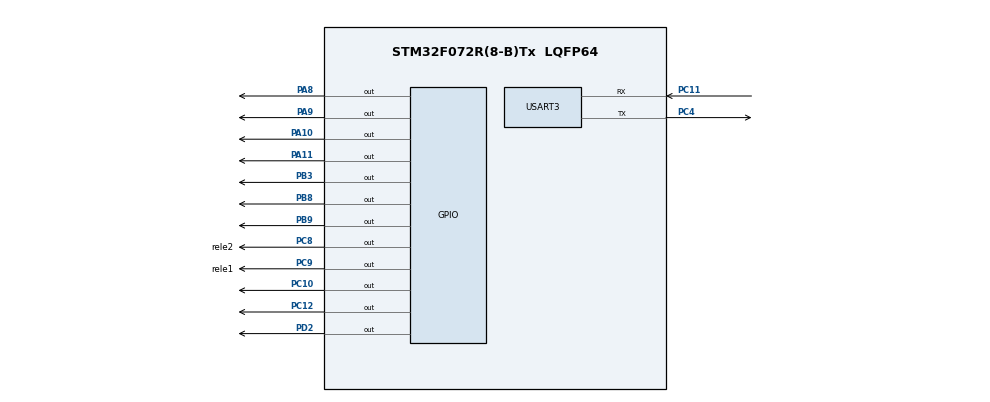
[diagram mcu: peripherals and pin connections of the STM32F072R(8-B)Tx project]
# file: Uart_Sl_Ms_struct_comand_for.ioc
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Mcu.Family=STM32F0
Mcu.Name=STM32F072R(8-B)Tx
Mcu.Package=LQFP64
NVIC.USART3_4_IRQn=true\:0\:0\:false\:false\:true\:true
PA10.Signal=GPIO_Output
PA11.Signal=GPIO_Output
PA8.Signal=GPIO_Output
PA9.Signal=GPIO_Output
PB3.Signal=GPIO_Output
PB8.GPIO_ModeDefaultOutputPP=GPIO_MODE_OUTPUT_PP
PB8.GPIO_PuPd=GPIO_PULLDOWN
PB8.PinState=GPIO_PIN_RESET
PB8.Signal=GPIO_Output
PB9.GPIO_PuPd=GPIO_PULLDOWN
PB9.PinState=GPIO_PIN_RESET
PB9.Signal=GPIO_Output
PC10.Signal=GPIO_Output
PC11.Mode=Asynchronous
PC11.Signal=USART3_RX
PC12.Signal=GPIO_Output
PC4.Mode=Asynchronous
PC4.Signal=USART3_TX
PC8.GPIO_Label=rele2
PC8.Signal=GPIO_Output
PC9.GPIO_Label=rele1
PC9.Signal=GPIO_Output
PD2.Signal=GPIO_Output
ProjectManager.HeapSize=0x200
ProjectManager.StackSize=0x400
ProjectManager.TargetToolchain=MDK-ARM V5
USART3.VirtualMode-Asynchronous=VM_ASYNC
USART3.WordLength=WORDLENGTH_8B
board=Uart_Sl_Ms_struct_comand_for

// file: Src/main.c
/**
  ******************************************************************************
  * @file           : main.c
  * @brief          : Main program body
  ******************************************************************************
  ** This notice applies to any and all portions of this file
  * that are not between comment pairs USER CODE BEGIN and
  * USER CODE END. Other portions of this file, whether
  * inserted by the user or by software development tools
  * are owned by their respective copyright owners.
  *
  * COPYRIGHT(c) 2018 STMicroelectronics
  *
  * Redistribution and use in source and binary forms, with or without modification,
  * are permitted provided that the following conditions are met:
  *   1. Redistributions of source code must retain the above copyright notice,
  *      this list of conditions and the following disclaimer.
  *   2. Redistributions in binary form must reproduce the above copyright notice,
  *      this list of conditions and the following disclaimer in the documentation
  *      and/or other materials provided with the distribution.
  *   3. Neither the name of STMicroelectronics nor the names of its contributors
  *      may be used to endorse or promote products derived from this software
  *      without specific prior written permission.
  *
  * THIS SOFTWARE IS PROVIDED BY THE COPYRIGHT HOLDERS AND CONTRIBUTORS "AS IS"
  * AND ANY EXPRESS OR IMPLIED WARRANTIES, INCLUDING, BUT NOT LIMITED TO, THE
  * IMPLIED WARRANTIES OF MERCHANTABILITY AND FITNESS FOR A PARTICULAR PURPOSE ARE
  * DISCLAIMED. IN NO EVENT SHALL THE COPYRIGHT HOLDER OR CONTRIBUTORS BE LIABLE
  * FOR ANY DIRECT, INDIRECT, INCIDENTAL, SPECIAL, EXEMPLARY, OR CONSEQUENTIAL
  * DAMAGES (INCLUDING, BUT NOT LIMITED TO, PROCUREMENT OF SUBSTITUTE GOODS OR
  * SERVICES; LOSS OF USE, DATA, OR PROFITS; OR BUSINESS INTERRUPTION) HOWEVER
  * CAUSED AND ON ANY THEORY OF LIABILITY, WHETHER IN CONTRACT, STRICT LIABILITY,
  * OR TORT (INCLUDING NEGLIGENCE OR OTHERWISE) ARISING IN ANY WAY OUT OF THE USE
  * OF THIS SOFTWARE, EVEN IF ADVISED OF THE POSSIBILITY OF SUCH DAMAGE.
  *
  ******************************************************************************
  */
#include "main.h"
#include "stm32f0xx_hal.h"

/* USER CODE BEGIN Includes */
     #define PROTOCOL_FAULT_TIMEOUT 			((uint8_t)0x01)
     #define PROTOCOL_FAULT_BADCRC 			((uint8_t)0x02)
     #define PROTOCOL_FAULT_UNKNOWNDATATYPE		((uint8_t)0x03)
     #define PROTOCOL_FAULT_UNKNOWNPAYLOAD		((uint8_t)0x04)
     #define PROTOCOL_FAULT_UNKNOWNLENGHT		((uint8_t)0x05)

/* USER CODE END Includes */

UART_HandleTypeDef huart3;

/* USER CODE BEGIN PV */
/* Private variables ---------------------------------------------------------*/
char Uart_texTX[]="Hi";
uint8_t Uart_texRX[8]	;
uint8_t uart_transmit[10];
uint8_t It =0;
uint8_t buff=0;

/* USER CODE END PV */
// typedef struct
// {	}Uart_Tx_OK_t ;

	/* Private function prototypes -----------------------------------------------*/
void SystemClock_Config(void);
static void MX_GPIO_Init(void);
static void MX_USART3_UART_Init(void);

/* USER CODE BEGIN PFP */
/* Private function prototypes -----------------------------------------------*/

/* USER CODE END PFP */

int main(void)
{
  /* USER CODE BEGIN 1 */
	for (uint8_t i =0; i<10;i++)
	{
		uart_transmit[i]=i;
	}

  /* USER CODE END 1 */

  /* MCU Configuration----------------------------------------------------------*/

  /* Reset of all peripherals, Initializes the Flash interface and the Systick. */
  HAL_Init();

  /* Configure the system clock */
  SystemClock_Config();

  /* Initialize all configured peripherals */
  MX_GPIO_Init();
  MX_USART3_UART_Init();

  /* Infinite loop */
  /* USER CODE BEGIN WHILE */
  while (1)
  {
	// HAL_UART_Receive_IT(&huart3,&It,1);
	if(buff>10)
	{
	buff=0;
	}

		HAL_UART_Receive_IT(&huart3,&uart_transmit[0],10);
		buff++;

	if (uart_transmit[7]>'5')
			{
		HAL_Delay(100);
				HAL_GPIO_TogglePin(GPIOB,GPIO_PIN_9);
			}

//	HAL_GPIO_TogglePin(GPIOB,GPIO_PIN_9);
//	HAL_Delay(100);
//	HAL_GPIO_TogglePin(GPIOB,GPIO_PIN_8);
//		HAL_UART_Transmit_IT(&huart3,(uint8_t*)Uart_texTX,sizeof(Uart_texTX));
    HAL_Delay(50);
	  HAL_UART_Transmit_IT(&huart3,&It,sizeof(It));
	}
  /* USER CODE END 3 */

}

void SystemClock_Config(void)
{

  RCC_OscInitTypeDef RCC_OscInitStruct;
  RCC_ClkInitTypeDef RCC_ClkInitStruct;

    /**Initializes the CPU, AHB and APB busses clocks
    */
  RCC_OscInitStruct.OscillatorType = RCC_OSCILLATORTYPE_HSI;
  RCC_OscInitStruct.HSIState = RCC_HSI_ON;
  RCC_OscInitStruct.HSICalibrationValue = 16;
  RCC_OscInitStruct.PLL.PLLState = RCC_PLL_NONE;
  if (HAL_RCC_OscConfig(&RCC_OscInitStruct) != HAL_OK)
  {
    _Error_Handler(__FILE__, __LINE__);
  }

    /**Initializes the CPU, AHB and APB busses clocks
    */
  RCC_ClkInitStruct.ClockType = RCC_CLOCKTYPE_HCLK|RCC_CLOCKTYPE_SYSCLK
                              |RCC_CLOCKTYPE_PCLK1;
  RCC_ClkInitStruct.SYSCLKSource = RCC_SYSCLKSOURCE_HSI;
  RCC_ClkInitStruct.AHBCLKDivider = RCC_SYSCLK_DIV1;
  RCC_ClkInitStruct.APB1CLKDivider = RCC_HCLK_DIV1;

  if (HAL_RCC_ClockConfig(&RCC_ClkInitStruct, FLASH_LATENCY_0) != HAL_OK)
  {
    _Error_Handler(__FILE__, __LINE__);
  }

    /**Configure the Systick interrupt time
    */
  HAL_SYSTICK_Config(HAL_RCC_GetHCLKFreq()/1000);

    /**Configure the Systick
    */
  HAL_SYSTICK_CLKSourceConfig(SYSTICK_CLKSOURCE_HCLK);

  /* SysTick_IRQn interrupt configuration */
  HAL_NVIC_SetPriority(SysTick_IRQn, 0, 0);
}

/* USART3 init function */
static void MX_USART3_UART_Init(void)
{

  huart3.Instance = USART3;
  huart3.Init.BaudRate = 38400;
  huart3.Init.WordLength = UART_WORDLENGTH_8B;
  huart3.Init.StopBits = UART_STOPBITS_1;
  huart3.Init.Parity = UART_PARITY_NONE;
  huart3.Init.Mode = UART_MODE_TX_RX;
  huart3.Init.HwFlowCtl = UART_HWCONTROL_NONE;
  huart3.Init.OverSampling = UART_OVERSAMPLING_16;
  huart3.Init.OneBitSampling = UART_ONE_BIT_SAMPLE_DISABLE;
  huart3.AdvancedInit.AdvFeatureInit = UART_ADVFEATURE_NO_INIT;
  if (HAL_UART_Init(&huart3) != HAL_OK)
  {
    _Error_Handler(__FILE__, __LINE__);
  }

}

/** Configure pins as
        * Analog
        * Input
        * Output
        * EVENT_OUT
        * EXTI
*/
static void MX_GPIO_Init(void)
{

  GPIO_InitTypeDef GPIO_InitStruct;

  /* GPIO Ports Clock Enable */
  __HAL_RCC_GPIOC_CLK_ENABLE();
  __HAL_RCC_GPIOA_CLK_ENABLE();
  __HAL_RCC_GPIOD_CLK_ENABLE();
  __HAL_RCC_GPIOB_CLK_ENABLE();

  /*Configure GPIO pin Output Level */
  HAL_GPIO_WritePin(GPIOC, rele2_Pin|rele1_Pin|GPIO_PIN_10|GPIO_PIN_12, GPIO_PIN_RESET);

  /*Configure GPIO pin Output Level */
  HAL_GPIO_WritePin(GPIOA, GPIO_PIN_8|GPIO_PIN_9|GPIO_PIN_10|GPIO_PIN_11, GPIO_PIN_RESET);

  /*Configure GPIO pin Output Level */
  HAL_GPIO_WritePin(GPIOD, GPIO_PIN_2, GPIO_PIN_RESET);

  /*Configure GPIO pin Output Level */
  HAL_GPIO_WritePin(GPIOB, GPIO_PIN_3|GPIO_PIN_8|GPIO_PIN_9, GPIO_PIN_RESET);

  /*Configure GPIO pins : rele2_Pin rele1_Pin PC10 PC12 */
  GPIO_InitStruct.Pin = rele2_Pin|rele1_Pin|GPIO_PIN_10|GPIO_PIN_12;
  GPIO_InitStruct.Mode = GPIO_MODE_OUTPUT_PP;
  GPIO_InitStruct.Pull = GPIO_NOPULL;
  GPIO_InitStruct.Speed = GPIO_SPEED_FREQ_LOW;
  HAL_GPIO_Init(GPIOC, &GPIO_InitStruct);

  /*Configure GPIO pins : PA8 PA9 PA10 PA11 */
  GPIO_InitStruct.Pin = GPIO_PIN_8|GPIO_PIN_9|GPIO_PIN_10|GPIO_PIN_11;
  GPIO_InitStruct.Mode = GPIO_MODE_OUTPUT_PP;
  GPIO_InitStruct.Pull = GPIO_NOPULL;
  GPIO_InitStruct.Speed = GPIO_SPEED_FREQ_LOW;
  HAL_GPIO_Init(GPIOA, &GPIO_InitStruct);

  /*Configure GPIO pin : PD2 */
  GPIO_InitStruct.Pin = GPIO_PIN_2;
  GPIO_InitStruct.Mode = GPIO_MODE_OUTPUT_PP;
  GPIO_InitStruct.Pull = GPIO_NOPULL;
  GPIO_InitStruct.Speed = GPIO_SPEED_FREQ_LOW;
  HAL_GPIO_Init(GPIOD, &GPIO_InitStruct);

  /*Configure GPIO pin : PB3 */
  GPIO_InitStruct.Pin = GPIO_PIN_3;
  GPIO_InitStruct.Mode = GPIO_MODE_OUTPUT_PP;
  GPIO_InitStruct.Pull = GPIO_NOPULL;
  GPIO_InitStruct.Speed = GPIO_SPEED_FREQ_LOW;
  HAL_GPIO_Init(GPIOB, &GPIO_InitStruct);

  /*Configure GPIO pins : PB8 PB9 */
  GPIO_InitStruct.Pin = GPIO_PIN_8|GPIO_PIN_9;
  GPIO_InitStruct.Mode = GPIO_MODE_OUTPUT_PP;
  GPIO_InitStruct.Pull = GPIO_PULLDOWN;
  GPIO_InitStruct.Speed = GPIO_SPEED_FREQ_LOW;
  HAL_GPIO_Init(GPIOB, &GPIO_InitStruct);

}

void _Error_Handler(char *file, int line)
{
  while(1)
  {
  }
}

/************************ (C) COPYRIGHT STMicroelectronics *****END OF FILE****/
